# STM32H743 register map
File version: 2.4
CPU: CM7 r0p1, little endian, MPU, FPU, 4 interrupt priority bits
Registers are 32-bit, read-write, reset 0x0 unless marked. A register's access mark holds for its fields unless they carry their own. Offsets are from the block's base; [hi:lo] are bit positions; {n}, {i} and the like mark numbered series; 'fields as' and 'values as' point back to an identical list.

## OTG1_HS_DEVICE — USB 1 OTG 高速接口
Base 0x40040800
Same registers: OTG2_HS_DEVICE 0x40080800
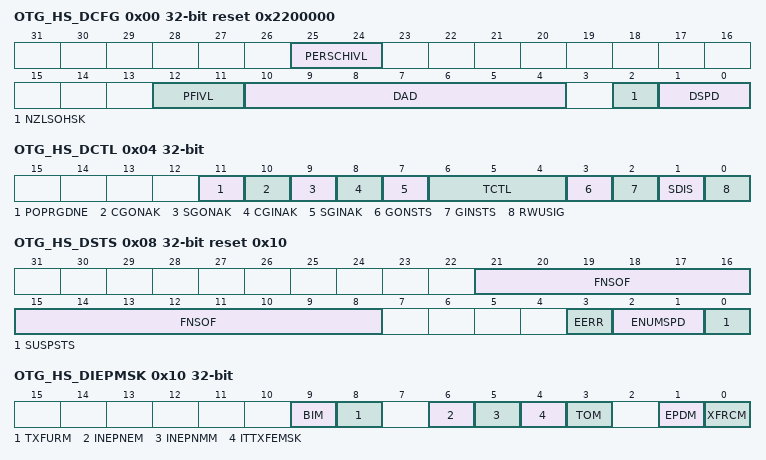
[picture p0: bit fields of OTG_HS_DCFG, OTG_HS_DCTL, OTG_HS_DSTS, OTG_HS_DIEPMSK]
0x00 OTG_HS_DCFG reset 0x2200000 — OTG_HS 设备配置寄存器
  [25:24] PERSCHIVL — 周期调度间隔
  [12:11] PFIVL — 周期（微）帧间隔
  [10:4] DAD — 设备地址
  [2] NZLSOHSK — 非零长度状态 OUT 握手
  [1:0] DSPD — 设备速度
0x04 OTG_HS_DCTL access per field — OTG_HS 设备控制寄存器
  [11] POPRGDNE rw — 上电编程完成
  [10] CGONAK wo — 清除全局 OUT NAK
  [9] SGONAK wo — 设置全局 OUT NAK
  [8] CGINAK wo — 清除全局 IN NAK
  [7] SGINAK wo — 设置全局 IN NAK
  [6:4] TCTL rw — 测试控制
  [3] GONSTS ro — 全局 OUT NAK 状态
  [2] GINSTS ro — 全局 IN NAK 状态
  [1] SDIS rw — 软断开
  [0] RWUSIG rw — 远程唤醒信号
0x08 OTG_HS_DSTS ro reset 0x10 — OTG_HS 设备状态寄存器
  [21:8] FNSOF — 接收到的 SOF 帧号
  [3] EERR — 异常错误
  [2:1] ENUMSPD — 枚举速度
  [0] SUSPSTS — 挂起状态
0x10 OTG_HS_DIEPMSK — OTG_HS 设备 IN 端点公共中断屏蔽寄存器
  [9] BIM — BNA 中断屏蔽
  [8] TXFURM — FIFO 欠载屏蔽
  [6] INEPNEM — IN 端点 NAK 有效屏蔽
  [5] INEPNMM — 收到 IN 令牌但 EP 不匹配屏蔽
  [4] ITTXFEMSK — TxFIFO 为空时收到 IN 令牌屏蔽
  [3] TOM — 超时条件屏蔽（非同步端点）
  [1] EPDM — 端点禁用中断屏蔽
  [0] XFRCM — 传输完成中断屏蔽
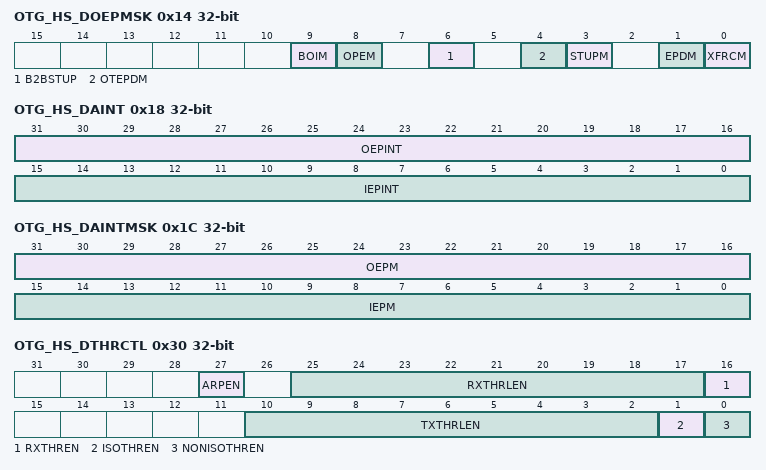
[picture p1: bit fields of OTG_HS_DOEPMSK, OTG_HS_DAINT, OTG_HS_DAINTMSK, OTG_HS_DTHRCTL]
0x14 OTG_HS_DOEPMSK — OTG_HS 设备 OUT 端点公共中断屏蔽寄存器
  [9] BOIM — BNA 中断屏蔽
  [8] OPEM — OUT 包错误屏蔽
  [6] B2BSTUP — 收到背靠背 SETUP 包屏蔽
  [4] OTEPDM — 端点禁用时收到 OUT 令牌屏蔽
  [3] STUPM — SETUP 阶段完成屏蔽
  [1] EPDM — 端点禁用中断屏蔽
  [0] XFRCM — 传输完成中断屏蔽
0x18 OTG_HS_DAINT ro — OTG_HS 设备全部端点中断寄存器
  [31:16] OEPINT — OUT 端点中断位
  [15:0] IEPINT — IN 端点中断位
0x1C OTG_HS_DAINTMSK — OTG_HS 全部端点中断屏蔽寄存器
  [31:16] OEPM — OUT EP 中断屏蔽位
  [15:0] IEPM — IN EP 中断屏蔽位
0x28 OTG_HS_DVBUSDIS reset 0x17D7 — OTG_HS 设备 VBUS 放电时间寄存器
  [15:0] VBUSDT — 设备 VBUS 放电时间
0x2C OTG_HS_DVBUSPULSE reset 0x5B8 — OTG_HS 设备 VBUS 脉冲时间寄存器
  [11:0] DVBUSP — 设备 VBUS 脉冲时间
0x30 OTG_HS_DTHRCTL — OTG_HS 设备阈值控制寄存器
  [27] ARPEN — 仲裁器驻留使能
  [25:17] RXTHRLEN — 接收阈值长度
  [16] RXTHREN — 接收阈值使能
  [10:2] TXTHRLEN — 发送阈值长度
  [1] ISOTHREN — 同步 IN 端点阈值使能
  [0] NONISOTHREN — 非同步 IN 端点阈值使能
0x34 OTG_HS_DIEPEMPMSK — OTG_HS 设备 IN 端点 FIFO 空中断屏蔽寄存器
  [15:0] INEPTXFEM — IN EP 发送 FIFO 空中断屏蔽位
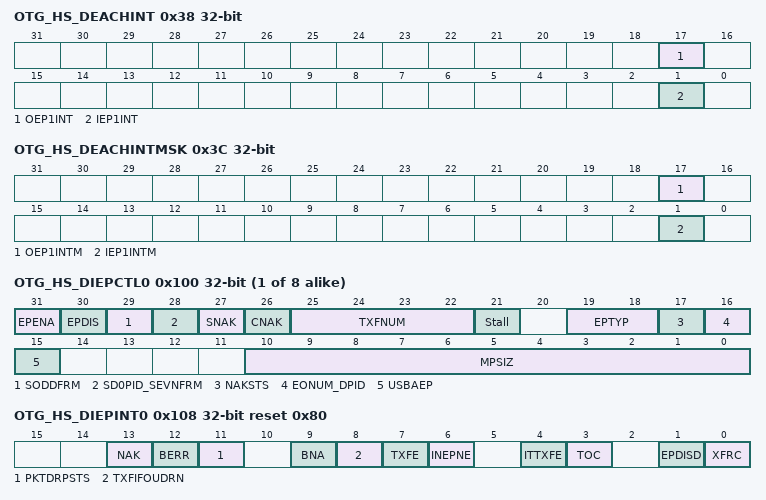
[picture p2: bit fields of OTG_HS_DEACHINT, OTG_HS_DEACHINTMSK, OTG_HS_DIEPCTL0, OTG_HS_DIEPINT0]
0x38 OTG_HS_DEACHINT — OTG_HS 设备各端点中断寄存器
  [17] OEP1INT — OUT 端点 1 中断位
  [1] IEP1INT — IN 端点 1 中断位
0x3C OTG_HS_DEACHINTMSK — OTG_HS 设备各端点中断屏蔽寄存器
  [17] OEP1INTM — OUT 端点 1 中断屏蔽位
  [1] IEP1INTM — IN 端点 1 中断屏蔽位
{0x100+0x20*i} OTG_HS_DIEPCTL{i} access per field (i=0..7) — OTG 设备端点 {i} 控制寄存器
  [31] EPENA rw — 端点使能
  [30] EPDIS rw — 端点禁用
  [29] SODDFRM wo — 设置奇帧
  [28] SD0PID_SEVNFRM wo — 设置 DATA0 PID
  [27] SNAK wo — 设置 NAK
  [26] CNAK wo — 清除 NAK
  [25:22] TXFNUM rw — TxFIFO 编号
  [21] Stall rw — STALL 握手
  [19:18] EPTYP rw — 端点类型
  [17] NAKSTS ro — NAK 状态
  [16] EONUM_DPID ro — 偶/奇帧
  [15] USBAEP rw — USB 活动端点
  [10:0] MPSIZ rw — 最大包长度
0x108 OTG_HS_DIEPINT0 access per field reset 0x80 — OTG 设备端点 0 中断寄存器
  [13] NAK rw — NAK 中断
  [12] BERR rw — Babble 错误中断
  [11] PKTDRPSTS rw — 包丢弃状态
  [9] BNA rw — 缓冲区不可用中断
  [8] TXFIFOUDRN rw — 发送 FIFO 欠载
  [7] TXFE ro — 发送 FIFO 空
  [6] INEPNE rw — IN 端点 NAK 有效
  [4] ITTXFE rw — TxFIFO 为空时收到 IN 令牌
  [3] TOC rw — 超时条件
  [1] EPDISD rw — 端点禁用中断
  [0] XFRC rw — 传输完成中断
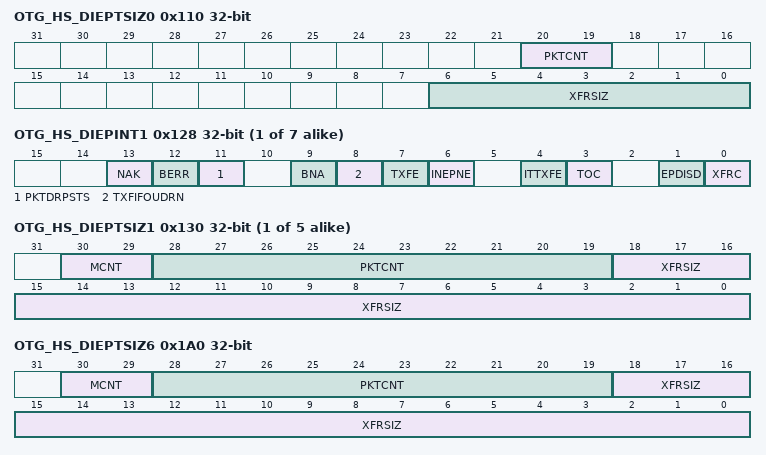
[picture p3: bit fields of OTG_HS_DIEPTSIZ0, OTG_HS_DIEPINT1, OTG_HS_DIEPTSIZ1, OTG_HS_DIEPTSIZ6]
0x110 OTG_HS_DIEPTSIZ0 — OTG_HS 设备 IN 端点 0 传输大小寄存器
  [20:19] PKTCNT — 包计数
  [6:0] XFRSIZ — 传输大小
{0xF4+0x20*i} OTG_HS_DIEPDMA{i} (i=1..5) — OTG_HS 设备端点 {i} DMA 地址寄存器
  [31:0] DMAADDR — DMA 地址
{0x118+0x20*i} OTG_HS_DTXFSTS{i} ro (i=0..5) — OTG_HS 设备 IN 端点发送 FIFO 状态寄存器
  [15:0] INEPTFSAV — IN 端点 TxFIFO 可用空间
{0x108+0x20*i} OTG_HS_DIEPINT{i} access per field (i=1..7) — OTG 设备端点 {i} 中断寄存器
  fields as OTG_HS_DIEPINT0
{0x110+0x20*i} OTG_HS_DIEPTSIZ{i} (i=1..5) — OTG_HS 设备端点 {i} 传输大小寄存器
  [30:29] MCNT — 多包计数
  [28:19] PKTCNT — 包计数
  [18:0] XFRSIZ — 传输大小
0x1A0 OTG_HS_DIEPTSIZ6 (alternate view of OTG_HS_DIEPCTL5) — OTG_HS 设备端点 6 传输大小寄存器
  [30:29] MCNT — 多包计数
  [28:19] PKTCNT — 包计数
  [18:0] XFRSIZ — 传输大小
0x1A4 OTG_HS_DTXFSTS6 — OTG_HS 设备 IN 端点发送 FIFO 状态寄存器
  [15:0] INEPTFSAV — IN 端点 TxFIFO 可用空间
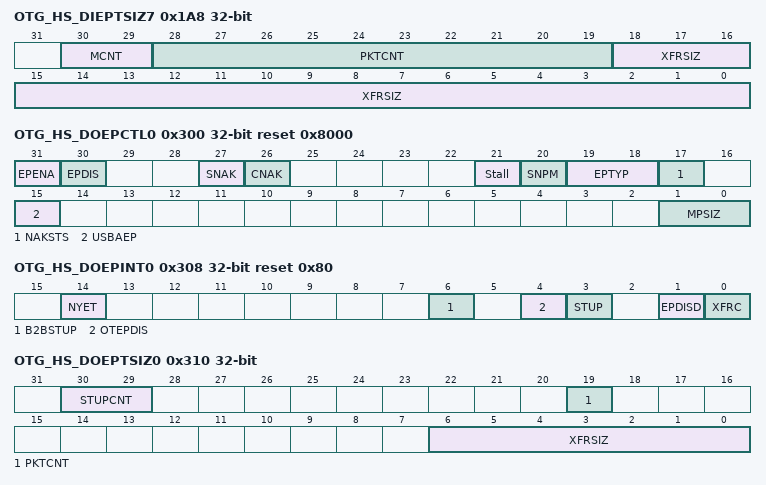
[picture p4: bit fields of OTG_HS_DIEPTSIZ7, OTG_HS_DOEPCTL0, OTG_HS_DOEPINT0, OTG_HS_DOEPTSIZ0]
0x1A8 OTG_HS_DIEPTSIZ7 (alternate view of OTG_HS_DIEPINT5) — OTG_HS 设备端点 7 传输大小寄存器
  [30:29] MCNT — 多包计数
  [28:19] PKTCNT — 包计数
  [18:0] XFRSIZ — 传输大小
0x1AC OTG_HS_DTXFSTS7 — OTG_HS 设备 IN 端点发送 FIFO 状态寄存器
  [15:0] INEPTFSAV — IN 端点 TxFIFO 可用空间
0x300 OTG_HS_DOEPCTL0 access per field reset 0x8000 — OTG_HS 设备 OUT 端点 0 控制寄存器
  [31] EPENA wo — 端点使能
  [30] EPDIS ro — 端点禁用
  [27] SNAK wo — 设置 NAK
  [26] CNAK wo — 清除 NAK
  [21] Stall rw — STALL 握手
  [20] SNPM rw — 监听模式
  [19:18] EPTYP ro — 端点类型
  [17] NAKSTS ro — NAK 状态
  [15] USBAEP ro — USB 活动端点
  [1:0] MPSIZ ro — 最大包长度
0x308 OTG_HS_DOEPINT0 reset 0x80 — OTG_HS 设备端点 0 中断寄存器
  [14] NYET — NYET 中断
  [6] B2BSTUP — 收到背靠背 SETUP 包
  [4] OTEPDIS — 端点禁用时收到 OUT 令牌
  [3] STUP — SETUP 阶段完成
  [1] EPDISD — 端点禁用中断
  [0] XFRC — 传输完成中断
0x310 OTG_HS_DOEPTSIZ0 — OTG_HS 设备 OUT 端点 0 传输大小寄存器
  [30:29] STUPCNT — SETUP 包计数
  [19] PKTCNT — 包计数
  [6:0] XFRSIZ — 传输大小
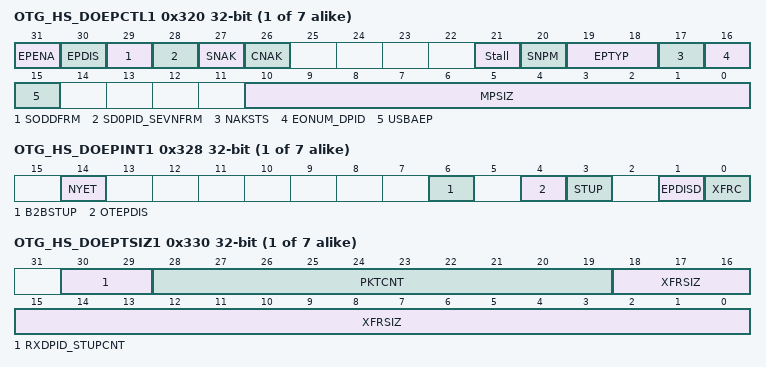
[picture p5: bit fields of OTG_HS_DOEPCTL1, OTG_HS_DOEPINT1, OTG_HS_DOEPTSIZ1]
{0x300+0x20*i} OTG_HS_DOEPCTL{i} access per field (i=1..7) — OTG 设备端点 {i} 控制寄存器
  [31] EPENA rw — 端点使能
  [30] EPDIS rw — 端点禁用
  [29] SODDFRM wo — 设置奇帧
  [28] SD0PID_SEVNFRM wo — 设置 DATA0 PID / 设置偶帧
  [27] SNAK wo — 设置 NAK
  [26] CNAK wo — 清除 NAK
  [21] Stall rw — STALL 握手
  [20] SNPM rw — 监听模式
  [19:18] EPTYP rw — 端点类型
  [17] NAKSTS ro — NAK 状态
  [16] EONUM_DPID ro — 偶/奇帧 / 端点数据 PID
  [15] USBAEP rw — USB 活动端点
  [10:0] MPSIZ rw — 最大包长度
{0x308+0x20*i} OTG_HS_DOEPINT{i} (i=1..7) — OTG_HS 设备端点 {i} 中断寄存器
  fields as OTG_HS_DOEPINT0
{0x310+0x20*i} OTG_HS_DOEPTSIZ{i} (i=1..7) — OTG_HS 设备端点 {i} 传输大小寄存器
  [30:29] RXDPID_STUPCNT — 接收数据 PID / SETUP 包计数
  [28:19] PKTCNT — 包计数
  [18:0] XFRSIZ — 传输大小
